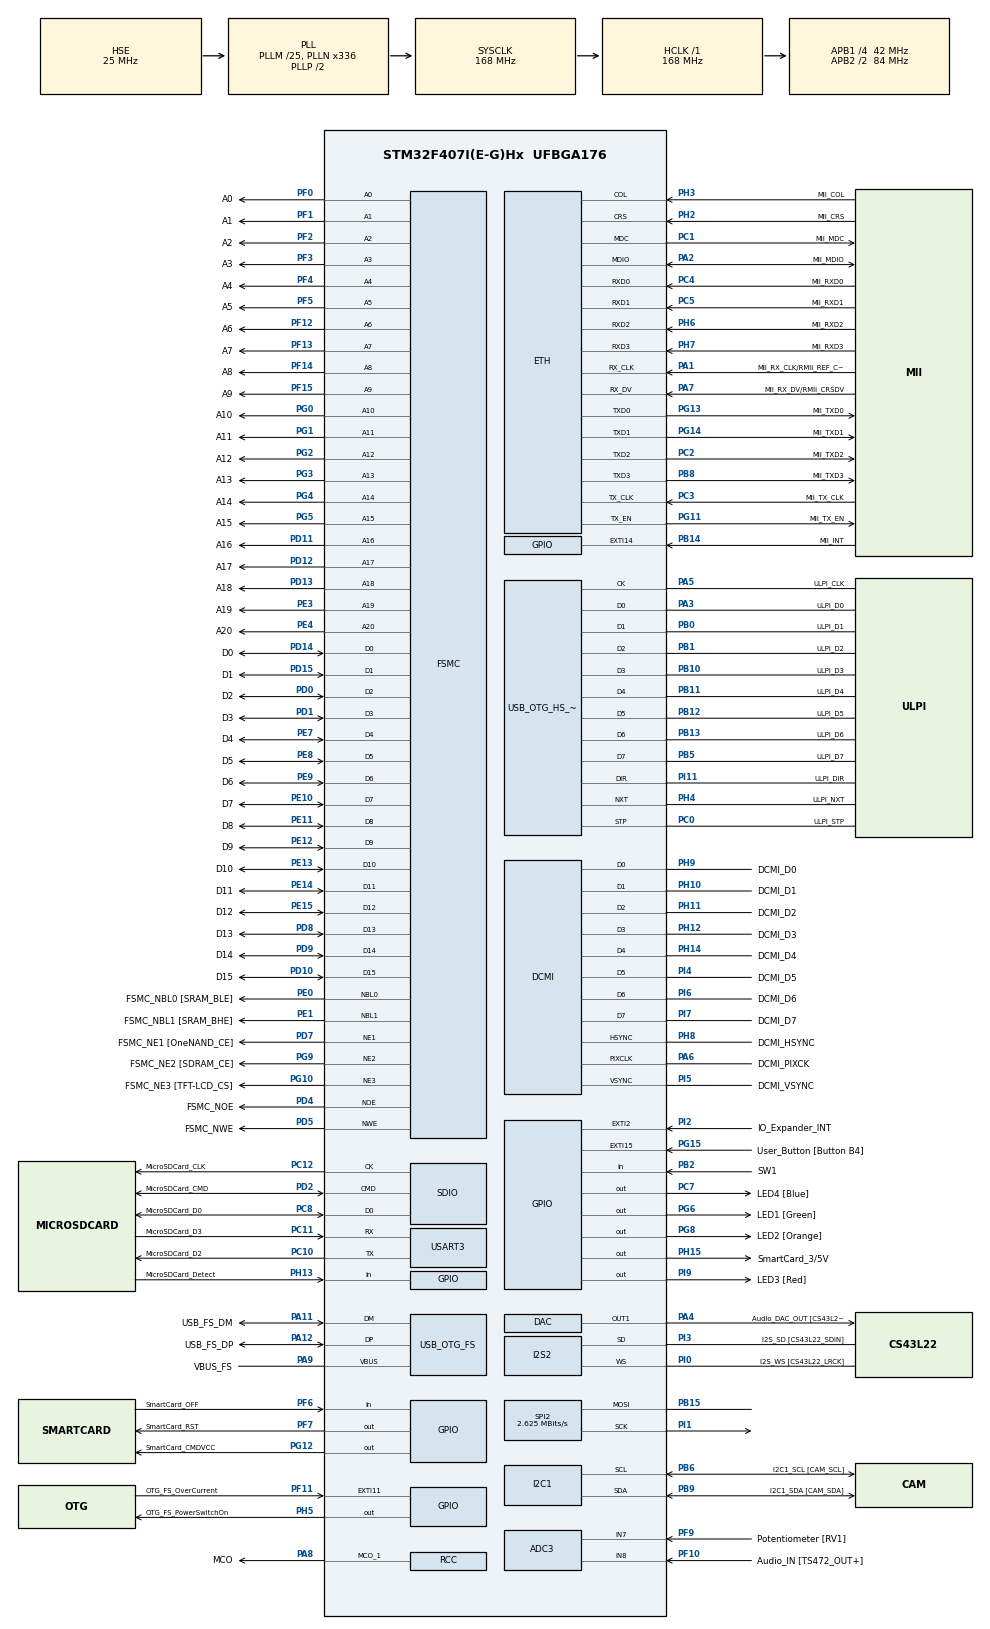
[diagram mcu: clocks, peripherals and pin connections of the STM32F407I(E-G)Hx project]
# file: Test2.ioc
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ADC3.Channel=ADC_CHANNEL_7
ADC3.Channel-0\#ChannelRegularConversion=ADC_CHANNEL_7
ADC3.NbrOfConversionFlag=1
ADC3.Rank-0\#ChannelRegularConversion=1
ADC3.SamplingTime-0\#ChannelRegularConversion=ADC_SAMPLETIME_3CYCLES
Dma.Request0=SPI2_TX
Dma.SPI2_TX.0.Direction=DMA_MEMORY_TO_PERIPH
Dma.SPI2_TX.0.FIFOMode=DMA_FIFOMODE_DISABLE
Dma.SPI2_TX.0.Instance=DMA1_Stream4
Dma.SPI2_TX.0.MemDataAlignment=DMA_MDATAALIGN_BYTE
Dma.SPI2_TX.0.MemInc=DMA_MINC_ENABLE
Dma.SPI2_TX.0.Mode=DMA_CIRCULAR
Dma.SPI2_TX.0.PeriphDataAlignment=DMA_PDATAALIGN_BYTE
Dma.SPI2_TX.0.PeriphInc=DMA_PINC_DISABLE
Dma.SPI2_TX.0.Priority=DMA_PRIORITY_LOW
ETH.MediaInterface=HAL_ETH_MII_MODE
FATFS.BSP.number=1
FATFS0.BSP.STBoard=false
FATFS0.BSP.api=Unknown
FATFS0.BSP.instance=PH13
FATFS0.BSP.ip=GPIO
FATFS0.BSP.mode=Input
FATFS0.BSP.name=Detect_SDIO
FATFS0.BSP.solution=PH13
FREERTOS.Tasks01=defaultTask,0,128,StartDefaultTask,Default,NULL,Dynamic,NULL,NULL
Mcu.Family=STM32F4
Mcu.Name=STM32F407I(E-G)Hx
Mcu.Package=UFBGA176
NVIC.DMA1_Stream4_IRQn=true\:5\:0\:false\:false\:true\:true\:false\:true\:true
NVIC.ETH_IRQn=true\:5\:0\:false\:false\:true\:true\:true\:true\:true
NVIC.OTG_FS_IRQn=true\:5\:0\:false\:false\:true\:true\:true\:true\:true
NVIC.PriorityGroup=NVIC_PRIORITYGROUP_4
PA0-WKUP.GPIO_Label=WAKEUP [Button B2]
PA0-WKUP.Signal=SYS_WKUP
PA1.GPIO_Label=MII_RX_CLK/RMII_REF_CLK
PA1.GPIO_Mode=GPIO_MODE_AF_PP
PA1.GPIO_PuPd=GPIO_NOPULL
PA1.GPIO_Speed=GPIO_SPEED_FREQ_LOW
PA1.Mode=MII
PA1.Signal=ETH_RX_CLK
PA10.GPIO_Label=USB_FS_ID
PA10.GPIO_Mode=GPIO_MODE_AF_PP
PA10.GPIO_PuPd=GPIO_NOPULL
PA10.GPIO_Speed=GPIO_SPEED_FREQ_LOW
PA10.Signal=USB_OTG_FS_ID
PA11.GPIO_Label=USB_FS_DM
PA11.GPIO_Mode=GPIO_MODE_AF_PP
PA11.GPIO_PuPd=GPIO_NOPULL
PA11.GPIO_Speed=GPIO_SPEED_FREQ_LOW
PA11.Mode=Host_Only
PA11.Signal=USB_OTG_FS_DM
PA12.GPIO_Label=USB_FS_DP
PA12.GPIO_Mode=GPIO_MODE_AF_PP
PA12.GPIO_PuPd=GPIO_NOPULL
PA12.GPIO_Speed=GPIO_SPEED_FREQ_LOW
PA12.Mode=Host_Only
PA12.Signal=USB_OTG_FS_DP
PA13.GPIO_Label=TMS/SWDIO
PA13.Mode=Serial_Wire
PA13.Signal=SYS_JTMS-SWDIO
PA14.GPIO_Label=TCK/SWCLK
PA14.Mode=Serial_Wire
PA14.Signal=SYS_JTCK-SWCLK
PA15.GPIO_Label=TDI
PA15.Signal=SYS_JTDI
PA2.GPIO_Label=MII_MDIO
PA2.GPIO_Mode=GPIO_MODE_AF_PP
PA2.GPIO_PuPd=GPIO_NOPULL
PA2.GPIO_Speed=GPIO_SPEED_FREQ_LOW
PA2.Mode=MII
PA2.Signal=ETH_MDIO
PA3.GPIO_Label=ULPI_D0
PA3.GPIO_Mode=GPIO_MODE_AF_PP
PA3.GPIO_PuPd=GPIO_NOPULL
PA3.GPIO_Speed=GPIO_SPEED_FREQ_VERY_HIGH
PA3.Mode=Host_HS
PA3.Signal=USB_OTG_HS_ULPI_D0
PA4.GPIO_Label=Audio_DAC_OUT [CS43L22_AIN1]
PA4.GPIO_Mode=GPIO_MODE_ANALOG
PA4.GPIO_PuPd=GPIO_NOPULL
PA4.Signal=COMP_DAC1_group
PA5.GPIO_Label=ULPI_CLK
PA5.GPIO_Mode=GPIO_MODE_AF_PP
PA5.GPIO_PuPd=GPIO_NOPULL
PA5.GPIO_Speed=GPIO_SPEED_FREQ_VERY_HIGH
PA5.Mode=Host_HS
PA5.Signal=USB_OTG_HS_ULPI_CK
PA6.GPIO_Label=DCMI_PIXCK
PA6.GPIO_Mode=GPIO_MODE_AF_PP
PA6.GPIO_PuPd=GPIO_NOPULL
PA6.GPIO_Speed=GPIO_SPEED_FREQ_LOW
PA6.Mode=Slave_8_bits_External_Synchro
PA6.Signal=DCMI_PIXCLK
PA7.GPIO_Label=MII_RX_DV/RMII_CRSDV
PA7.GPIO_Mode=GPIO_MODE_AF_PP
PA7.GPIO_PuPd=GPIO_NOPULL
PA7.GPIO_Speed=GPIO_SPEED_FREQ_LOW
PA7.Mode=MII
PA7.Signal=ETH_RX_DV
PA8.GPIO_Label=MCO
PA8.GPIO_Mode=GPIO_MODE_AF_PP
PA8.GPIO_PuPd=GPIO_NOPULL
PA8.GPIO_Speed=GPIO_SPEED_FREQ_LOW
PA8.Mode=Clock-out-1
PA8.Signal=RCC_MCO_1
PA9.GPIO_Label=VBUS_FS
PA9.GPIO_Mode=GPIO_MODE_INPUT
PA9.GPIO_PuPd=GPIO_NOPULL
PA9.Mode=Activate_VBUS
PA9.Signal=USB_OTG_FS_VBUS
PB0.GPIO_Label=ULPI_D1
PB0.GPIO_Mode=GPIO_MODE_AF_PP
PB0.GPIO_PuPd=GPIO_NOPULL
PB0.GPIO_Speed=GPIO_SPEED_FREQ_VERY_HIGH
PB0.Mode=Host_HS
PB0.Signal=USB_OTG_HS_ULPI_D1
PB1.GPIO_Label=ULPI_D2
PB1.GPIO_Mode=GPIO_MODE_AF_PP
PB1.GPIO_PuPd=GPIO_NOPULL
PB1.GPIO_Speed=GPIO_SPEED_FREQ_VERY_HIGH
PB1.Mode=Host_HS
PB1.Signal=USB_OTG_HS_ULPI_D2
PB10.GPIO_Label=ULPI_D3
PB10.GPIO_Mode=GPIO_MODE_AF_PP
PB10.GPIO_PuPd=GPIO_NOPULL
PB10.GPIO_Speed=GPIO_SPEED_FREQ_VERY_HIGH
PB10.Mode=Host_HS
PB10.Signal=USB_OTG_HS_ULPI_D3
PB11.GPIO_Label=ULPI_D4
PB11.GPIO_Mode=GPIO_MODE_AF_PP
PB11.GPIO_PuPd=GPIO_NOPULL
PB11.GPIO_Speed=GPIO_SPEED_FREQ_VERY_HIGH
PB11.Mode=Host_HS
PB11.Signal=USB_OTG_HS_ULPI_D4
PB12.GPIO_Label=ULPI_D5
PB12.GPIO_Mode=GPIO_MODE_AF_PP
PB12.GPIO_PuPd=GPIO_NOPULL
PB12.GPIO_Speed=GPIO_SPEED_FREQ_VERY_HIGH
PB12.Mode=Host_HS
PB12.Signal=USB_OTG_HS_ULPI_D5
PB13.GPIO_Label=ULPI_D6
PB13.GPIO_Mode=GPIO_MODE_AF_PP
PB13.GPIO_PuPd=GPIO_NOPULL
PB13.GPIO_Speed=GPIO_SPEED_FREQ_VERY_HIGH
PB13.Mode=Host_HS
PB13.Signal=USB_OTG_HS_ULPI_D6
PB14.GPIO_Label=MII_INT
PB14.GPIO_ModeDefaultEXTI=GPIO_MODE_EVT_RISING
PB14.GPIO_PuPd=GPIO_NOPULL
PB14.Signal=GPXTI14
PB15.Mode=Simplex_Bidirectional_Master
PB15.Signal=SPI2_MOSI
PB2.GPIO_Label=SW1
PB2.GPIO_Mode=GPIO_MODE_INPUT
PB2.GPIO_PuPd=GPIO_NOPULL
PB2.Signal=GPIO_Input
PB3.GPIO_Label=TDO/SWO
PB3.Signal=SYS_JTDO-SWO
PB4.GPIO_Label=TRST
PB4.Signal=SYS_JTRST
PB5.GPIO_Label=ULPI_D7
PB5.GPIO_Mode=GPIO_MODE_AF_PP
PB5.GPIO_PuPd=GPIO_NOPULL
PB5.GPIO_Speed=GPIO_SPEED_FREQ_VERY_HIGH
PB5.Mode=Host_HS
PB5.Signal=USB_OTG_HS_ULPI_D7
PB6.GPIO_Label=I2C1_SCL [CAM_SCL]
PB6.GPIO_Mode=GPIO_MODE_AF_OD
PB6.GPIO_Pu=GPIO_PULLUP
PB6.GPIO_PuPd=GPIO_NOPULL
PB6.GPIO_Speed=GPIO_SPEED_FREQ_LOW
PB6.Mode=I2C
PB6.Signal=I2C1_SCL
PB7.GPIO_Label=FSMC_NL [OneNAND_AVD]
PB7.GPIO_Mode=GPIO_MODE_AF_PP
PB7.GPIO_PuPd=GPIO_NOPULL
PB7.GPIO_Speed=GPIO_SPEED_FREQ_LOW
PB7.Signal=FSMC_NL
PB8.GPIO_Label=MII_TXD3
PB8.GPIO_Mode=GPIO_MODE_AF_PP
PB8.GPIO_PuPd=GPIO_NOPULL
PB8.GPIO_Speed=GPIO_SPEED_FREQ_LOW
PB8.Mode=MII
PB8.Signal=ETH_TXD3
PB9.GPIO_Label=I2C1_SDA [CAM_SDA]
PB9.GPIO_Mode=GPIO_MODE_AF_OD
PB9.GPIO_Pu=GPIO_PULLUP
PB9.GPIO_PuPd=GPIO_NOPULL
PB9.GPIO_Speed=GPIO_SPEED_FREQ_LOW
PB9.Mode=I2C
PB9.Signal=I2C1_SDA
PC0.GPIO_Label=ULPI_STP
PC0.GPIO_Mode=GPIO_MODE_AF_PP
PC0.GPIO_PuPd=GPIO_NOPULL
PC0.GPIO_Speed=GPIO_SPEED_FREQ_VERY_HIGH
PC0.Mode=Host_HS
PC0.Signal=USB_OTG_HS_ULPI_STP
PC1.GPIO_Label=MII_MDC
PC1.GPIO_Mode=GPIO_MODE_AF_PP
PC1.GPIO_PuPd=GPIO_NOPULL
PC1.GPIO_Speed=GPIO_SPEED_FREQ_LOW
PC1.Mode=MII
PC1.Signal=ETH_MDC
PC10.GPIO_Label=MicroSDCard_D2
PC10.GPIO_Mode=GPIO_MODE_AF_PP
PC10.GPIO_PuPd=GPIO_NOPULL
PC10.GPIO_Speed=GPIO_SPEED_FREQ_LOW
PC10.Mode=Asynchronous
PC10.Signal=USART3_TX
PC11.GPIO_Label=MicroSDCard_D3
PC11.GPIO_Mode=GPIO_MODE_AF_PP
PC11.GPIO_PuPd=GPIO_NOPULL
PC11.GPIO_Speed=GPIO_SPEED_FREQ_LOW
PC11.Mode=Asynchronous
PC11.Signal=USART3_RX
PC12.GPIO_Label=MicroSDCard_CLK
PC12.GPIO_Mode=GPIO_MODE_AF_PP
PC12.GPIO_PuPd=GPIO_NOPULL
PC12.GPIO_Speed=GPIO_SPEED_FREQ_LOW
PC12.Mode=SD_1_bit
PC12.Signal=SDIO_CK
PC13-ANTI_TAMP.GPIO_Label=Anti_Tamper [Button B3]
PC13-ANTI_TAMP.Signal=RTC_AF1
PC14-OSC32_IN.GPIO_Label=PC14-OSC32_IN
PC14-OSC32_IN.Mode=LSE-External-Oscillator
PC14-OSC32_IN.Signal=RCC_OSC32_IN
PC15-OSC32_OUT.GPIO_Label=PC15-OSC32_OUT
PC15-OSC32_OUT.Mode=LSE-External-Oscillator
PC15-OSC32_OUT.Signal=RCC_OSC32_OUT
PC2.GPIO_Label=MII_TXD2
PC2.GPIO_Mode=GPIO_MODE_AF_PP
PC2.GPIO_PuPd=GPIO_NOPULL
PC2.GPIO_Speed=GPIO_SPEED_FREQ_LOW
PC2.Mode=MII
PC2.Signal=ETH_TXD2
PC3.GPIO_Label=MII_TX_CLK
PC3.GPIO_Mode=GPIO_MODE_AF_PP
PC3.GPIO_PuPd=GPIO_NOPULL
PC3.GPIO_Speed=GPIO_SPEED_FREQ_LOW
PC3.Mode=MII
PC3.Signal=ETH_TX_CLK
PC4.GPIO_Label=MII_RXD0
PC4.GPIO_Mode=GPIO_MODE_AF_PP
PC4.GPIO_PuPd=GPIO_NOPULL
PC4.GPIO_Speed=GPIO_SPEED_FREQ_LOW
PC4.Mode=MII
PC4.Signal=ETH_RXD0
PC5.GPIO_Label=MII_RXD1
PC5.GPIO_Mode=GPIO_MODE_AF_PP
PC5.GPIO_PuPd=GPIO_NOPULL
PC5.GPIO_Speed=GPIO_SPEED_FREQ_LOW
PC5.Mode=MII
PC5.Signal=ETH_RXD1
PC7.GPIO_Label=LED4 [Blue]
PC7.GPIO_Mode=GPIO_MODE_OUTPUT_PP
PC7.GPIO_ModeDefaultOutputPP=GPIO_MODE_OUTPUT_PP
PC7.GPIO_PuPd=GPIO_NOPULL
PC7.GPIO_Speed=GPIO_SPEED_FREQ_LOW
PC7.Signal=GPIO_Output
PC8.GPIO_Label=MicroSDCard_D0
PC8.GPIO_Mode=GPIO_MODE_AF_PP
PC8.GPIO_PuPd=GPIO_NOPULL
PC8.GPIO_Speed=GPIO_SPEED_FREQ_LOW
PC8.Mode=SD_1_bit
PC8.Signal=SDIO_D0
PC9.GPIO_Label=MicroSDCard_D1
PC9.GPIO_Mode=GPIO_MODE_AF_PP
PC9.GPIO_PuPd=GPIO_NOPULL
PC9.GPIO_Speed=GPIO_SPEED_FREQ_LOW
PC9.Signal=SDIO_D1
PD0.GPIO_Label=D2
PD0.GPIO_Mode=GPIO_MODE_AF_PP
PD0.GPIO_PuPd=GPIO_NOPULL
PD0.GPIO_Speed=GPIO_SPEED_FREQ_LOW
PD0.Signal=FSMC_D2_DA2
PD1.GPIO_Label=D3
PD1.GPIO_Mode=GPIO_MODE_AF_PP
PD1.GPIO_PuPd=GPIO_NOPULL
PD1.GPIO_Speed=GPIO_SPEED_FREQ_LOW
PD1.Signal=FSMC_D3_DA3
PD10.GPIO_Label=D15
PD10.GPIO_Mode=GPIO_MODE_AF_PP
PD10.GPIO_PuPd=GPIO_NOPULL
PD10.GPIO_Speed=GPIO_SPEED_FREQ_LOW
PD10.Signal=FSMC_D15_DA15
PD11.GPIO_Label=A16
PD11.GPIO_Mode=GPIO_MODE_AF_PP
PD11.GPIO_PuPd=GPIO_NOPULL
PD11.GPIO_Speed=GPIO_SPEED_FREQ_LOW
PD11.Signal=FSMC_A16_CLE
PD12.GPIO_Label=A17
PD12.GPIO_Mode=GPIO_MODE_AF_PP
PD12.GPIO_PuPd=GPIO_NOPULL
PD12.GPIO_Speed=GPIO_SPEED_FREQ_LOW
PD12.Signal=FSMC_A17_ALE
PD13.GPIO_Label=A18
PD13.GPIO_Mode=GPIO_MODE_AF_PP
PD13.GPIO_PuPd=GPIO_NOPULL
PD13.GPIO_Speed=GPIO_SPEED_FREQ_LOW
PD13.Signal=FSMC_A18
PD14.GPIO_Label=D0
PD14.GPIO_Mode=GPIO_MODE_AF_PP
PD14.GPIO_PuPd=GPIO_NOPULL
PD14.GPIO_Speed=GPIO_SPEED_FREQ_LOW
PD14.Signal=FSMC_D0_DA0
PD15.GPIO_Label=D1
PD15.GPIO_Mode=GPIO_MODE_AF_PP
PD15.GPIO_PuPd=GPIO_NOPULL
PD15.GPIO_Speed=GPIO_SPEED_FREQ_LOW
PD15.Signal=FSMC_D1_DA1
PD2.GPIO_Label=MicroSDCard_CMD
PD2.GPIO_Mode=GPIO_MODE_AF_PP
PD2.GPIO_PuPd=GPIO_NOPULL
PD2.GPIO_Speed=GPIO_SPEED_FREQ_LOW
PD2.Mode=SD_1_bit
PD2.Signal=SDIO_CMD
PD3.GPIO_Label=FSMC_CLK [OneNAND_CLK]
PD3.GPIO_Mode=GPIO_MODE_AF_PP
PD3.GPIO_PuPd=GPIO_NOPULL
PD3.GPIO_Speed=GPIO_SPEED_FREQ_LOW
PD3.Signal=FSMC_CLK
PD4.GPIO_Label=FSMC_NOE
PD4.GPIO_Mode=GPIO_MODE_AF_PP
PD4.GPIO_PuPd=GPIO_NOPULL
PD4.GPIO_Speed=GPIO_SPEED_FREQ_LOW
PD4.Signal=FSMC_NOE
PD5.GPIO_Label=FSMC_NWE
PD5.GPIO_Mode=GPIO_MODE_AF_PP
PD5.GPIO_PuPd=GPIO_NOPULL
PD5.GPIO_Speed=GPIO_SPEED_FREQ_LOW
PD5.Signal=FSMC_NWE
PD6.GPIO_Label=FSMC_NWAIT [OneNAND_RDY]
PD6.GPIO_Mode=GPIO_MODE_AF_PP
PD6.GPIO_PuPd=GPIO_NOPULL
PD6.GPIO_Speed=GPIO_SPEED_FREQ_LOW
PD6.Signal=FSMC_NWAIT
PD7.GPIO_Label=FSMC_NE1 [OneNAND_CE]
PD7.GPIO_Mode=GPIO_MODE_AF_PP
PD7.GPIO_PuPd=GPIO_NOPULL
PD7.GPIO_Speed=GPIO_SPEED_FREQ_LOW
PD7.Mode=NorPsramChipSelect1_1
PD7.Signal=FSMC_NE1
PD8.GPIO_Label=D13
PD8.GPIO_Mode=GPIO_MODE_AF_PP
PD8.GPIO_PuPd=GPIO_NOPULL
PD8.GPIO_Speed=GPIO_SPEED_FREQ_LOW
PD8.Signal=FSMC_D13_DA13
PD9.GPIO_Label=D14
PD9.GPIO_Mode=GPIO_MODE_AF_PP
PD9.GPIO_PuPd=GPIO_NOPULL
PD9.GPIO_Speed=GPIO_SPEED_FREQ_LOW
PD9.Signal=FSMC_D14_DA14
PE0.GPIO_Label=FSMC_NBL0 [SRAM_BLE]
PE0.GPIO_Mode=GPIO_MODE_AF_PP
PE0.GPIO_PuPd=GPIO_NOPULL
PE0.GPIO_Speed=GPIO_SPEED_FREQ_LOW
PE0.Signal=FSMC_NBL0
PE1.GPIO_Label=FSMC_NBL1 [SRAM_BHE]
PE1.GPIO_Mode=GPIO_MODE_AF_PP
PE1.GPIO_PuPd=GPIO_NOPULL
PE1.GPIO_Speed=GPIO_SPEED_FREQ_LOW
PE1.Signal=FSMC_NBL1
PE10.GPIO_Label=D7
PE10.GPIO_Mode=GPIO_MODE_AF_PP
PE10.GPIO_PuPd=GPIO_NOPULL
PE10.GPIO_Speed=GPIO_SPEED_FREQ_LOW
PE10.Signal=FSMC_D7_DA7
PE11.GPIO_Label=D8
PE11.GPIO_Mode=GPIO_MODE_AF_PP
PE11.GPIO_PuPd=GPIO_NOPULL
PE11.GPIO_Speed=GPIO_SPEED_FREQ_LOW
PE11.Signal=FSMC_D8_DA8
PE12.GPIO_Label=D9
PE12.GPIO_Mode=GPIO_MODE_AF_PP
PE12.GPIO_PuPd=GPIO_NOPULL
PE12.GPIO_Speed=GPIO_SPEED_FREQ_LOW
PE12.Signal=FSMC_D9_DA9
PE13.GPIO_Label=D10
PE13.GPIO_Mode=GPIO_MODE_AF_PP
PE13.GPIO_PuPd=GPIO_NOPULL
PE13.GPIO_Speed=GPIO_SPEED_FREQ_LOW
PE13.Signal=FSMC_D10_DA10
PE14.GPIO_Label=D11
PE14.GPIO_Mode=GPIO_MODE_AF_PP
PE14.GPIO_PuPd=GPIO_NOPULL
PE14.GPIO_Speed=GPIO_SPEED_FREQ_LOW
PE14.Signal=FSMC_D11_DA11
PE15.GPIO_Label=D12
PE15.GPIO_Mode=GPIO_MODE_AF_PP
PE15.GPIO_PuPd=GPIO_NOPULL
PE15.GPIO_Speed=GPIO_SPEED_FREQ_LOW
PE15.Signal=FSMC_D12_DA12
PE2.GPIO_Label=TRACE_CLK
PE2.Signal=SYS_TRACECLK
PE3.GPIO_Label=A19
PE3.GPIO_Mode=GPIO_MODE_AF_PP
PE3.GPIO_PuPd=GPIO_NOPULL
PE3.GPIO_Speed=GPIO_SPEED_FREQ_LOW
PE3.Signal=FSMC_A19
PE4.GPIO_Label=A20
PE4.GPIO_Mode=GPIO_MODE_AF_PP
PE4.GPIO_PuPd=GPIO_NOPULL
PE4.GPIO_Speed=GPIO_SPEED_FREQ_LOW
PE4.Signal=FSMC_A20
PE5.GPIO_Label=TRACE_D2
PE5.Signal=SYS_TRACED2
PE6.GPIO_Label=TRACE_D3
PE6.Signal=SYS_TRACED3
PE7.GPIO_Label=D4
PE7.GPIO_Mode=GPIO_MODE_AF_PP
PE7.GPIO_PuPd=GPIO_NOPULL
PE7.GPIO_Speed=GPIO_SPEED_FREQ_LOW
PE7.Signal=FSMC_D4_DA4
PE8.GPIO_Label=D5
PE8.GPIO_Mode=GPIO_MODE_AF_PP
PE8.GPIO_PuPd=GPIO_NOPULL
PE8.GPIO_Speed=GPIO_SPEED_FREQ_LOW
PE8.Signal=FSMC_D5_DA5
PE9.GPIO_Label=D6
PE9.GPIO_Mode=GPIO_MODE_AF_PP
PE9.GPIO_PuPd=GPIO_NOPULL
PE9.GPIO_Speed=GPIO_SPEED_FREQ_LOW
PE9.Signal=FSMC_D6_DA6
PF0.GPIO_Label=A0
PF0.GPIO_Mode=GPIO_MODE_AF_PP
PF0.GPIO_PuPd=GPIO_NOPULL
PF0.GPIO_Speed=GPIO_SPEED_FREQ_LOW
PF0.Signal=FSMC_A0
PF1.GPIO_Label=A1
PF1.GPIO_Mode=GPIO_MODE_AF_PP
PF1.GPIO_PuPd=GPIO_NOPULL
PF1.GPIO_Speed=GPIO_SPEED_FREQ_LOW
PF1.Signal=FSMC_A1
PF10.GPIO_Label=Audio_IN [TS472_OUT+]
PF10.GPIO_Mode=GPIO_MODE_ANALOG
PF10.GPIO_PuPd=GPIO_NOPULL
PF10.Mode=IN8
PF10.Signal=ADC3_IN8
PF11.GPIO_Label=OTG_FS_OverCurrent
PF11.GPIO_ModeDefaultEXTI=GPIO_MODE_EVT_RISING
PF11.GPIO_PuPd=GPIO_NOPULL
PF11.Signal=GPXTI11
PF12.GPIO_Label=A6
PF12.GPIO_Mode=GPIO_MODE_AF_PP
PF12.GPIO_PuPd=GPIO_NOPULL
PF12.GPIO_Speed=GPIO_SPEED_FREQ_LOW
PF12.Signal=FSMC_A6
PF13.GPIO_Label=A7
PF13.GPIO_Mode=GPIO_MODE_AF_PP
PF13.GPIO_PuPd=GPIO_NOPULL
PF13.GPIO_Speed=GPIO_SPEED_FREQ_LOW
PF13.Signal=FSMC_A7
PF14.GPIO_Label=A8
PF14.GPIO_Mode=GPIO_MODE_AF_PP
PF14.GPIO_PuPd=GPIO_NOPULL
PF14.GPIO_Speed=GPIO_SPEED_FREQ_LOW
PF14.Signal=FSMC_A8
PF15.GPIO_Label=A9
PF15.GPIO_Mode=GPIO_MODE_AF_PP
PF15.GPIO_PuPd=GPIO_NOPULL
PF15.GPIO_Speed=GPIO_SPEED_FREQ_LOW
PF15.Signal=FSMC_A9
PF2.GPIO_Label=A2
PF2.GPIO_Mode=GPIO_MODE_AF_PP
PF2.GPIO_PuPd=GPIO_NOPULL
PF2.GPIO_Speed=GPIO_SPEED_FREQ_LOW
PF2.Signal=FSMC_A2
PF3.GPIO_Label=A3
PF3.GPIO_Mode=GPIO_MODE_AF_PP
PF3.GPIO_PuPd=GPIO_NOPULL
PF3.GPIO_Speed=GPIO_SPEED_FREQ_LOW
PF3.Signal=FSMC_A3
PF4.GPIO_Label=A4
PF4.GPIO_Mode=GPIO_MODE_AF_PP
PF4.GPIO_PuPd=GPIO_NOPULL
PF4.GPIO_Speed=GPIO_SPEED_FREQ_LOW
PF4.Signal=FSMC_A4
PF5.GPIO_Label=A5
PF5.GPIO_Mode=GPIO_MODE_AF_PP
PF5.GPIO_PuPd=GPIO_NOPULL
PF5.GPIO_Speed=GPIO_SPEED_FREQ_LOW
PF5.Signal=FSMC_A5
PF6.GPIO_Label=SmartCard_OFF
PF6.GPIO_Mode=GPIO_MODE_INPUT
PF6.GPIO_PuPd=GPIO_NOPULL
PF6.Signal=GPIO_Input
PF7.GPIO_Label=SmartCard_RST
PF7.GPIO_Mode=GPIO_MODE_OUTPUT_PP
PF7.GPIO_ModeDefaultOutputPP=GPIO_MODE_OUTPUT_PP
PF7.GPIO_PuPd=GPIO_NOPULL
PF7.GPIO_Speed=GPIO_SPEED_FREQ_LOW
PF7.Signal=GPIO_Output
PF9.GPIO_Label=Potentiometer [RV1]
PF9.GPIO_Mode=GPIO_MODE_ANALOG
PF9.GPIO_PuPd=GPIO_NOPULL
PF9.Mode=IN7
PF9.Signal=ADC3_IN7
PG0.GPIO_Label=A10
PG0.GPIO_Mode=GPIO_MODE_AF_PP
PG0.GPIO_PuPd=GPIO_NOPULL
PG0.GPIO_Speed=GPIO_SPEED_FREQ_LOW
PG0.Signal=FSMC_A10
PG1.GPIO_Label=A11
PG1.GPIO_Mode=GPIO_MODE_AF_PP
PG1.GPIO_PuPd=GPIO_NOPULL
PG1.GPIO_Speed=GPIO_SPEED_FREQ_LOW
PG1.Signal=FSMC_A11
PG10.GPIO_Label=FSMC_NE3 [TFT-LCD_CS]
PG10.GPIO_Mode=GPIO_MODE_AF_PP
PG10.GPIO_PuPd=GPIO_NOPULL
PG10.GPIO_Speed=GPIO_SPEED_FREQ_LOW
PG10.Mode=NorPsramChipSelect3_3
PG10.Signal=FSMC_NE3
PG11.GPIO_Label=MII_TX_EN
PG11.GPIO_Mode=GPIO_MODE_AF_PP
PG11.GPIO_PuPd=GPIO_NOPULL
PG11.GPIO_Speed=GPIO_SPEED_FREQ_LOW
PG11.Mode=MII
PG11.Signal=ETH_TX_EN
PG12.GPIO_Label=SmartCard_CMDVCC
PG12.GPIO_Mode=GPIO_MODE_OUTPUT_PP
PG12.GPIO_ModeDefaultOutputPP=GPIO_MODE_OUTPUT_PP
PG12.GPIO_PuPd=GPIO_NOPULL
PG12.GPIO_Speed=GPIO_SPEED_FREQ_LOW
PG12.Signal=GPIO_Output
PG13.GPIO_Label=MII_TXD0
PG13.GPIO_Mode=GPIO_MODE_AF_PP
PG13.GPIO_PuPd=GPIO_NOPULL
PG13.GPIO_Speed=GPIO_SPEED_FREQ_LOW
PG13.Mode=MII
PG13.Signal=ETH_TXD0
PG14.GPIO_Label=MII_TXD1
PG14.GPIO_Mode=GPIO_MODE_AF_PP
PG14.GPIO_PuPd=GPIO_NOPULL
PG14.GPIO_Speed=GPIO_SPEED_FREQ_LOW
PG14.Mode=MII
PG14.Signal=ETH_TXD1
PG15.GPIO_Label=User_Button [Button B4]
PG15.GPIO_ModeDefaultEXTI=GPIO_MODE_EVT_RISING
PG15.GPIO_PuPd=GPIO_NOPULL
PG15.Signal=GPXTI15
PG2.GPIO_Label=A12
PG2.GPIO_Mode=GPIO_MODE_AF_PP
PG2.GPIO_PuPd=GPIO_NOPULL
PG2.GPIO_Speed=GPIO_SPEED_FREQ_LOW
PG2.Signal=FSMC_A12
PG3.GPIO_Label=A13
PG3.GPIO_Mode=GPIO_MODE_AF_PP
PG3.GPIO_PuPd=GPIO_NOPULL
PG3.GPIO_Speed=GPIO_SPEED_FREQ_LOW
PG3.Signal=FSMC_A13
PG4.GPIO_Label=A14
PG4.GPIO_Mode=GPIO_MODE_AF_PP
PG4.GPIO_PuPd=GPIO_NOPULL
PG4.GPIO_Speed=GPIO_SPEED_FREQ_LOW
PG4.Signal=FSMC_A14
PG5.GPIO_Label=A15
PG5.GPIO_Mode=GPIO_MODE_AF_PP
PG5.GPIO_PuPd=GPIO_NOPULL
PG5.GPIO_Speed=GPIO_SPEED_FREQ_LOW
PG5.Signal=FSMC_A15
PG6.GPIO_Label=LED1 [Green]
PG6.GPIO_Mode=GPIO_MODE_OUTPUT_PP
PG6.GPIO_ModeDefaultOutputPP=GPIO_MODE_OUTPUT_PP
PG6.GPIO_PuPd=GPIO_NOPULL
PG6.GPIO_Speed=GPIO_SPEED_FREQ_LOW
PG6.Signal=GPIO_Output
PG7.GPIO_Label=SmartCard_CLK
PG7.GPIO_Mode=GPIO_MODE_AF_PP
PG7.GPIO_PuPd=GPIO_NOPULL
PG7.GPIO_Speed=GPIO_SPEED_FREQ_LOW
PG7.Signal=USART6_CK
PG8.GPIO_Label=LED2 [Orange]
PG8.GPIO_Mode=GPIO_MODE_OUTPUT_PP
PG8.GPIO_ModeDefaultOutputPP=GPIO_MODE_OUTPUT_PP
PG8.GPIO_PuPd=GPIO_NOPULL
PG8.GPIO_Speed=GPIO_SPEED_FREQ_LOW
PG8.Signal=GPIO_Output
PG9.GPIO_Label=FSMC_NE2 [SDRAM_CE]
PG9.GPIO_Mode=GPIO_MODE_AF_PP
PG9.GPIO_PuPd=GPIO_NOPULL
PG9.GPIO_Speed=GPIO_SPEED_FREQ_LOW
PG9.Mode=NorPsramChipSelect2_2
PG9.Signal=FSMC_NE2
PH0-OSC_IN.GPIO_Label=PH0-OSC_IN
PH0-OSC_IN.Mode=HSE-External-Oscillator
PH0-OSC_IN.Signal=RCC_OSC_IN
PH1-OSC_OUT.GPIO_Label=PH1-OSC_OUT
PH1-OSC_OUT.Mode=HSE-External-Oscillator
PH1-OSC_OUT.Signal=RCC_OSC_OUT
PH10.GPIO_Label=DCMI_D1
PH10.GPIO_Mode=GPIO_MODE_AF_PP
PH10.GPIO_PuPd=GPIO_NOPULL
PH10.GPIO_Speed=GPIO_SPEED_FREQ_LOW
PH10.Mode=Slave_8_bits_External_Synchro
PH10.Signal=DCMI_D1
PH11.GPIO_Label=DCMI_D2
PH11.GPIO_Mode=GPIO_MODE_AF_PP
PH11.GPIO_PuPd=GPIO_NOPULL
PH11.GPIO_Speed=GPIO_SPEED_FREQ_LOW
PH11.Mode=Slave_8_bits_External_Synchro
PH11.Signal=DCMI_D2
PH12.GPIO_Label=DCMI_D3
PH12.GPIO_Mode=GPIO_MODE_AF_PP
PH12.GPIO_PuPd=GPIO_NOPULL
PH12.GPIO_Speed=GPIO_SPEED_FREQ_LOW
PH12.Mode=Slave_8_bits_External_Synchro
PH12.Signal=DCMI_D3
PH13.GPIO_Label=MicroSDCard_Detect
PH13.GPIO_Mode=GPIO_MODE_INPUT
PH13.GPIO_PuPd=GPIO_PULLUP
PH13.Signal=GPIO_Input
PH14.GPIO_Label=DCMI_D4
PH14.GPIO_Mode=GPIO_MODE_AF_PP
PH14.GPIO_PuPd=GPIO_NOPULL
PH14.GPIO_Speed=GPIO_SPEED_FREQ_LOW
PH14.Mode=Slave_8_bits_External_Synchro
PH14.Signal=DCMI_D4
PH15.GPIO_Label=SmartCard_3/5V
PH15.GPIO_Mode=GPIO_MODE_OUTPUT_PP
PH15.GPIO_ModeDefaultOutputPP=GPIO_MODE_OUTPUT_PP
PH15.GPIO_PuPd=GPIO_NOPULL
PH15.GPIO_Speed=GPIO_SPEED_FREQ_LOW
PH15.Signal=GPIO_Output
PH2.GPIO_Label=MII_CRS
PH2.GPIO_Mode=GPIO_MODE_AF_PP
PH2.GPIO_PuPd=GPIO_NOPULL
PH2.GPIO_Speed=GPIO_SPEED_FREQ_LOW
PH2.Mode=MII
PH2.Signal=ETH_CRS
PH3.GPIO_Label=MII_COL
PH3.GPIO_Mode=GPIO_MODE_AF_PP
PH3.GPIO_PuPd=GPIO_NOPULL
PH3.GPIO_Speed=GPIO_SPEED_FREQ_LOW
PH3.Mode=MII
PH3.Signal=ETH_COL
PH4.GPIO_Label=ULPI_NXT
PH4.GPIO_Mode=GPIO_MODE_AF_PP
PH4.GPIO_PuPd=GPIO_NOPULL
PH4.GPIO_Speed=GPIO_SPEED_FREQ_VERY_HIGH
PH4.Mode=Host_HS
PH4.Signal=USB_OTG_HS_ULPI_NXT
PH5.GPIO_Label=OTG_FS_PowerSwitchOn
PH5.GPIO_Mode=GPIO_MODE_OUTPUT_PP
PH5.GPIO_ModeDefaultOutputPP=GPIO_MODE_OUTPUT_PP
PH5.GPIO_PuPd=GPIO_NOPULL
PH5.GPIO_Speed=GPIO_SPEED_FREQ_LOW
PH5.Signal=GPIO_Output
PH6.GPIO_Label=MII_RXD2
PH6.GPIO_Mode=GPIO_MODE_AF_PP
PH6.GPIO_PuPd=GPIO_NOPULL
PH6.GPIO_Speed=GPIO_SPEED_FREQ_LOW
PH6.Mode=MII
PH6.Signal=ETH_RXD2
PH7.GPIO_Label=MII_RXD3
PH7.GPIO_Mode=GPIO_MODE_AF_PP
PH7.GPIO_PuPd=GPIO_NOPULL
PH7.GPIO_Speed=GPIO_SPEED_FREQ_LOW
PH7.Mode=MII
PH7.Signal=ETH_RXD3
PH8.GPIO_Label=DCMI_HSYNC
PH8.GPIO_Mode=GPIO_MODE_AF_PP
PH8.GPIO_PuPd=GPIO_NOPULL
PH8.GPIO_Speed=GPIO_SPEED_FREQ_LOW
PH8.Mode=Slave_8_bits_External_Synchro
PH8.Signal=DCMI_HSYNC
PH9.GPIO_Label=DCMI_D0
PH9.GPIO_Mode=GPIO_MODE_AF_PP
PH9.GPIO_PuPd=GPIO_NOPULL
PH9.GPIO_Speed=GPIO_SPEED_FREQ_LOW
PH9.Mode=Slave_8_bits_External_Synchro
PH9.Signal=DCMI_D0
PI0.GPIO_Label=I2S_WS [CS43L22_LRCK]
PI0.GPIO_Mode=GPIO_MODE_AF_PP
PI0.GPIO_PuPd=GPIO_NOPULL
PI0.GPIO_Speed=GPIO_SPEED_FREQ_LOW
PI0.Mode=Half_Duplex_Master
PI0.Signal=I2S2_WS
PI1.Mode=Simplex_Bidirectional_Master
PI1.Signal=SPI2_SCK
PI10.GPIO_Label=MII_RX_ER
PI10.GPIO_Mode=GPIO_MODE_AF_PP
PI10.GPIO_PuPd=GPIO_NOPULL
PI10.GPIO_Speed=GPIO_SPEED_FREQ_LOW
PI10.Signal=ETH_RX_ER
PI11.GPIO_Label=ULPI_DIR
PI11.GPIO_Mode=GPIO_MODE_AF_PP
PI11.GPIO_PuPd=GPIO_NOPULL
PI11.GPIO_Speed=GPIO_SPEED_FREQ_VERY_HIGH
PI11.Mode=Host_HS
PI11.Signal=USB_OTG_HS_ULPI_DIR
PI2.GPIO_Label=IO_Expander_INT
PI2.GPIO_ModeDefaultEXTI=GPIO_MODE_EVT_RISING
PI2.GPIO_PuPd=GPIO_NOPULL
PI2.Signal=GPXTI2
PI3.GPIO_Label=I2S_SD [CS43L22_SDIN]
PI3.GPIO_Mode=GPIO_MODE_AF_PP
PI3.GPIO_PuPd=GPIO_NOPULL
PI3.GPIO_Speed=GPIO_SPEED_FREQ_LOW
PI3.Mode=Half_Duplex_Master
PI3.Signal=I2S2_SD
PI4.GPIO_Label=DCMI_D5
PI4.GPIO_Mode=GPIO_MODE_AF_PP
PI4.GPIO_PuPd=GPIO_NOPULL
PI4.GPIO_Speed=GPIO_SPEED_FREQ_LOW
PI4.Mode=Slave_8_bits_External_Synchro
PI4.Signal=DCMI_D5
PI5.GPIO_Label=DCMI_VSYNC
PI5.GPIO_Mode=GPIO_MODE_AF_PP
PI5.GPIO_PuPd=GPIO_NOPULL
PI5.GPIO_Speed=GPIO_SPEED_FREQ_LOW
PI5.Mode=Slave_8_bits_External_Synchro
PI5.Signal=DCMI_VSYNC
PI6.GPIO_Label=DCMI_D6
PI6.GPIO_Mode=GPIO_MODE_AF_PP
PI6.GPIO_PuPd=GPIO_NOPULL
PI6.GPIO_Speed=GPIO_SPEED_FREQ_LOW
PI6.Mode=Slave_8_bits_External_Synchro
PI6.Signal=DCMI_D6
PI7.GPIO_Label=DCMI_D7
PI7.GPIO_Mode=GPIO_MODE_AF_PP
PI7.GPIO_PuPd=GPIO_NOPULL
PI7.GPIO_Speed=GPIO_SPEED_FREQ_LOW
PI7.Mode=Slave_8_bits_External_Synchro
PI7.Signal=DCMI_D7
PI9.GPIO_Label=LED3 [Red]
PI9.GPIO_Mode=GPIO_MODE_OUTPUT_PP
PI9.GPIO_ModeDefaultOutputPP=GPIO_MODE_OUTPUT_PP
PI9.GPIO_PuPd=GPIO_NOPULL
PI9.GPIO_Speed=GPIO_SPEED_FREQ_LOW
PI9.Signal=GPIO_Output
ProjectManager.HeapSize=0x200
ProjectManager.StackSize=0x400
ProjectManager.TargetToolchain=STM32CubeIDE
RCC.48MHZClocksFreq_Value=48000000
RCC.AHBFreq_Value=168000000
RCC.APB1CLKDivider=RCC_HCLK_DIV4
RCC.APB1Freq_Value=42000000
RCC.APB1TimFreq_Value=84000000
RCC.APB2CLKDivider=RCC_HCLK_DIV2
RCC.APB2Freq_Value=84000000
RCC.APB2TimFreq_Value=168000000
RCC.CortexFreq_Value=168000000
RCC.HCLKFreq_Value=168000000
RCC.HSE_VALUE=25000000
RCC.HSI_VALUE=16000000
RCC.PLLM=25
RCC.PLLN=336
RCC.PLLQ=7
RCC.RCC_MCO1Source=RCC_MCO1SOURCE_HSE
RCC.SYSCLKFreq_VALUE=168000000
RCC.SYSCLKSource=RCC_SYSCLKSOURCE_PLLCLK
RCC.VCOOutputFreq_Value=336000000
SDIO.BusWide-SD_1_bit=SDIO_BUS_WIDE_1B
SH.COMP_DAC1_group.0=DAC_OUT1,DAC_OUT1
SH.FSMC_A0.0=FSMC_A0,21b-a1
SH.FSMC_A0.1=FSMC_A0,21b-a2
SH.FSMC_A0.2=FSMC_A0,21b-a3
SH.FSMC_A1.0=FSMC_A1,21b-a1
SH.FSMC_A1.1=FSMC_A1,21b-a2
SH.FSMC_A1.2=FSMC_A1,21b-a3
SH.FSMC_A10.0=FSMC_A10,21b-a1
SH.FSMC_A10.1=FSMC_A10,21b-a2
SH.FSMC_A10.2=FSMC_A10,21b-a3
SH.FSMC_A11.0=FSMC_A11,21b-a1
SH.FSMC_A11.1=FSMC_A11,21b-a2
SH.FSMC_A11.2=FSMC_A11,21b-a3
SH.FSMC_A12.0=FSMC_A12,21b-a1
SH.FSMC_A12.1=FSMC_A12,21b-a2
SH.FSMC_A12.2=FSMC_A12,21b-a3
SH.FSMC_A13.0=FSMC_A13,21b-a1
SH.FSMC_A13.1=FSMC_A13,21b-a2
SH.FSMC_A13.2=FSMC_A13,21b-a3
SH.FSMC_A14.0=FSMC_A14,21b-a1
SH.FSMC_A14.1=FSMC_A14,21b-a2
SH.FSMC_A14.2=FSMC_A14,21b-a3
SH.FSMC_A15.0=FSMC_A15,21b-a1
SH.FSMC_A15.1=FSMC_A15,21b-a2
SH.FSMC_A15.2=FSMC_A15,21b-a3
SH.FSMC_A16_CLE.0=FSMC_A16,21b-a1
SH.FSMC_A16_CLE.1=FSMC_A16,21b-a2
SH.FSMC_A16_CLE.2=FSMC_A16,21b-a3
SH.FSMC_A17_ALE.0=FSMC_A17,21b-a1
SH.FSMC_A17_ALE.1=FSMC_A17,21b-a2
SH.FSMC_A17_ALE.2=FSMC_A17,21b-a3
SH.FSMC_A18.0=FSMC_A18,21b-a1
SH.FSMC_A18.1=FSMC_A18,21b-a2
SH.FSMC_A18.2=FSMC_A18,21b-a3
SH.FSMC_A19.0=FSMC_A19,21b-a1
SH.FSMC_A19.1=FSMC_A19,21b-a2
SH.FSMC_A19.2=FSMC_A19,21b-a3
SH.FSMC_A2.0=FSMC_A2,21b-a1
SH.FSMC_A2.1=FSMC_A2,21b-a2
SH.FSMC_A2.2=FSMC_A2,21b-a3
SH.FSMC_A20.0=FSMC_A20,21b-a1
SH.FSMC_A20.1=FSMC_A20,21b-a2
SH.FSMC_A20.2=FSMC_A20,21b-a3
SH.FSMC_A3.0=FSMC_A3,21b-a1
SH.FSMC_A3.1=FSMC_A3,21b-a2
SH.FSMC_A3.2=FSMC_A3,21b-a3
SH.FSMC_A4.0=FSMC_A4,21b-a1
SH.FSMC_A4.1=FSMC_A4,21b-a2
SH.FSMC_A4.2=FSMC_A4,21b-a3
SH.FSMC_A5.0=FSMC_A5,21b-a1
SH.FSMC_A5.1=FSMC_A5,21b-a2
SH.FSMC_A5.2=FSMC_A5,21b-a3
SH.FSMC_A6.0=FSMC_A6,21b-a1
SH.FSMC_A6.1=FSMC_A6,21b-a2
SH.FSMC_A6.2=FSMC_A6,21b-a3
SH.FSMC_A7.0=FSMC_A7,21b-a1
SH.FSMC_A7.1=FSMC_A7,21b-a2
SH.FSMC_A7.2=FSMC_A7,21b-a3
SH.FSMC_A8.0=FSMC_A8,21b-a1
SH.FSMC_A8.1=FSMC_A8,21b-a2
SH.FSMC_A8.2=FSMC_A8,21b-a3
SH.FSMC_A9.0=FSMC_A9,21b-a1
SH.FSMC_A9.1=FSMC_A9,21b-a2
SH.FSMC_A9.2=FSMC_A9,21b-a3
SH.FSMC_CLK.0=FSMC_CLK
SH.FSMC_D0_DA0.0=FSMC_D0,16b-d1
SH.FSMC_D0_DA0.1=FSMC_D0,16b-d2
SH.FSMC_D0_DA0.2=FSMC_D0,16b-d3
SH.FSMC_D10_DA10.0=FSMC_D10,16b-d1
SH.FSMC_D10_DA10.1=FSMC_D10,16b-d2
SH.FSMC_D10_DA10.2=FSMC_D10,16b-d3
SH.FSMC_D11_DA11.0=FSMC_D11,16b-d1
SH.FSMC_D11_DA11.1=FSMC_D11,16b-d2
SH.FSMC_D11_DA11.2=FSMC_D11,16b-d3
SH.FSMC_D12_DA12.0=FSMC_D12,16b-d1
SH.FSMC_D12_DA12.1=FSMC_D12,16b-d2
SH.FSMC_D12_DA12.2=FSMC_D12,16b-d3
SH.FSMC_D13_DA13.0=FSMC_D13,16b-d1
SH.FSMC_D13_DA13.1=FSMC_D13,16b-d2
SH.FSMC_D13_DA13.2=FSMC_D13,16b-d3
SH.FSMC_D14_DA14.0=FSMC_D14,16b-d1
SH.FSMC_D14_DA14.1=FSMC_D14,16b-d2
SH.FSMC_D14_DA14.2=FSMC_D14,16b-d3
SH.FSMC_D15_DA15.0=FSMC_D15,16b-d1
SH.FSMC_D15_DA15.1=FSMC_D15,16b-d2
SH.FSMC_D15_DA15.2=FSMC_D15,16b-d3
SH.FSMC_D1_DA1.0=FSMC_D1,16b-d1
SH.FSMC_D1_DA1.1=FSMC_D1,16b-d2
SH.FSMC_D1_DA1.2=FSMC_D1,16b-d3
SH.FSMC_D2_DA2.0=FSMC_D2,16b-d1
SH.FSMC_D2_DA2.1=FSMC_D2,16b-d2
SH.FSMC_D2_DA2.2=FSMC_D2,16b-d3
SH.FSMC_D3_DA3.0=FSMC_D3,16b-d1
SH.FSMC_D3_DA3.1=FSMC_D3,16b-d2
SH.FSMC_D3_DA3.2=FSMC_D3,16b-d3
SH.FSMC_D4_DA4.0=FSMC_D4,16b-d1
SH.FSMC_D4_DA4.1=FSMC_D4,16b-d2
SH.FSMC_D4_DA4.2=FSMC_D4,16b-d3
SH.FSMC_D5_DA5.0=FSMC_D5,16b-d1
SH.FSMC_D5_DA5.1=FSMC_D5,16b-d2
SH.FSMC_D5_DA5.2=FSMC_D5,16b-d3
SH.FSMC_D6_DA6.0=FSMC_D6,16b-d1
SH.FSMC_D6_DA6.1=FSMC_D6,16b-d2
SH.FSMC_D6_DA6.2=FSMC_D6,16b-d3
SH.FSMC_D7_DA7.0=FSMC_D7,16b-d1
SH.FSMC_D7_DA7.1=FSMC_D7,16b-d2
SH.FSMC_D7_DA7.2=FSMC_D7,16b-d3
SH.FSMC_D8_DA8.0=FSMC_D8,16b-d1
SH.FSMC_D8_DA8.1=FSMC_D8,16b-d2
SH.FSMC_D8_DA8.2=FSMC_D8,16b-d3
SH.FSMC_D9_DA9.0=FSMC_D9,16b-d1
SH.FSMC_D9_DA9.1=FSMC_D9,16b-d2
SH.FSMC_D9_DA9.2=FSMC_D9,16b-d3
SH.FSMC_NBL0.0=FSMC_NBL0,2ByteEnable2
SH.FSMC_NBL1.0=FSMC_NBL1,2ByteEnable2
SH.FSMC_NL.0=FSMC_NL
SH.FSMC_NOE.0=FSMC_NOE,NorFlash1
SH.FSMC_NOE.1=FSMC_NOE,Sram2
SH.FSMC_NOE.2=FSMC_NOE,Sram3
SH.FSMC_NWAIT.0=FSMC_NWAIT
SH.FSMC_NWE.0=FSMC_NWE,NorFlash1
SH.FSMC_NWE.1=FSMC_NWE,Sram2
SH.FSMC_NWE.2=FSMC_NWE,Sram3
SPI2.BaudRatePrescaler=SPI_BAUDRATEPRESCALER_16
SPI2.CalculateBaudRate=2.625 MBits/s
SPI2.Direction=SPI_DIRECTION_1LINE
SPI2.Mode=SPI_MODE_MASTER
SPI2.VirtualType=VM_MASTER
USART3.VirtualMode=VM_ASYNC
USB_HOST.BSP.number=1
USB_HOST.USBH_HandleTypeDef-CDC_FS=hUsbHostFS
USB_HOST.USBH_USE_OS-CDC_FS=0
USB_HOST.VirtualModeFS=Cdc
USB_HOST0.BSP.STBoard=false
USB_HOST0.BSP.api=Unknown
USB_HOST0.BSP.instance=PH5
USB_HOST0.BSP.ip=GPIO
USB_HOST0.BSP.mode=Output
USB_HOST0.BSP.name=Drive_VBUS_FS
USB_HOST0.BSP.solution=PH5
USB_OTG_FS.VirtualMode=Host_Only
USB_OTG_FS.phy_itface=HCD_PHY_EMBEDDED
USB_OTG_HS.VirtualMode-Host_HS=Host_HS
VP_FATFS_VS_SDIO.Mode=SDIO
VP_FREERTOS_VS_CMSIS_V1.Mode=CMSIS_V1
VP_USB_HOST_VS_USB_HOST_CDC_FS.Mode=CDC_FS
board=STM3240G-EVAL

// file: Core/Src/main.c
/* USER CODE BEGIN Header */
/**
  ******************************************************************************
  * @file           : main.c
  * @brief          : Main program body
  ******************************************************************************
  * @attention
  *
  * Copyright (c) 2024 STMicroelectronics.
  * All rights reserved.
  *
  * This software is licensed under terms that can be found in the LICENSE file
  * in the root directory of this software component.
  * If no LICENSE file comes with this software, it is provided AS-IS.
  *
  ******************************************************************************
  */
/* USER CODE END Header */
#include "main.h"
#include "string.h"
#include "cmsis_os.h"
#include "fatfs.h"
#include "usb_host.h"

ETH_TxPacketConfig TxConfig;
ETH_DMADescTypeDef  DMARxDscrTab[ETH_RX_DESC_CNT]; /* Ethernet Rx DMA Descriptors */
ETH_DMADescTypeDef  DMATxDscrTab[ETH_TX_DESC_CNT]; /* Ethernet Tx DMA Descriptors */

ADC_HandleTypeDef hadc3;

DAC_HandleTypeDef hdac;

DCMI_HandleTypeDef hdcmi;

ETH_HandleTypeDef heth;

I2C_HandleTypeDef hi2c1;

SD_HandleTypeDef hsd;

SPI_HandleTypeDef hspi2;
DMA_HandleTypeDef hdma_spi2_tx;

UART_HandleTypeDef huart3;

HCD_HandleTypeDef hhcd_USB_OTG_HS;

NOR_HandleTypeDef hnor1;
SRAM_HandleTypeDef hsram2;
SRAM_HandleTypeDef hsram3;

osThreadId defaultTaskHandle;
/* USER CODE BEGIN PV */
//Frame buffers
/*Static or global buffer(s). The second buffer is optional*/
static lv_color_t buf_1[3200]; //TODO: Chose a buffer size. DISPLAY_WIDTH * 10 is one suggestion.

/* USER CODE END PV */

void SystemClock_Config(void);
static void MX_GPIO_Init(void);
static void MX_DMA_Init(void);
static void MX_ADC3_Init(void);
static void MX_DAC_Init(void);
static void MX_DCMI_Init(void);
static void MX_ETH_Init(void);
static void MX_FSMC_Init(void);
static void MX_I2C1_Init(void);
static void MX_SDIO_SD_Init(void);
static void MX_USART3_UART_Init(void);
static void MX_USB_OTG_HS_HCD_Init(void);
static void MX_SPI2_Init(void);
void StartDefaultTask(void const * argument);

int main(void)
{

  /* MCU Configuration--------------------------------------------------------*/

  /* Reset of all peripherals, Initializes the Flash interface and the Systick. */
  HAL_Init();

  /* Configure the system clock */
  SystemClock_Config();

  /* Initialize all configured peripherals */
  MX_GPIO_Init();
  MX_DMA_Init();
  MX_ADC3_Init();
  MX_DAC_Init();
  MX_DCMI_Init();
  MX_ETH_Init();
  MX_FSMC_Init();
  MX_I2C1_Init();
  MX_SDIO_SD_Init();
  MX_USART3_UART_Init();
  MX_USB_OTG_HS_HCD_Init();
  MX_FATFS_Init();
  MX_SPI2_Init();
  /* USER CODE BEGIN 2 */
  //BSP_LCD_Init();
  lv_init();
  Display_Init();
  BSP_SRAM_Init();
    /* Initialize the touch screen */
    BSP_TS_Init(BSP_LCD_GetXSize(), BSP_LCD_GetYSize());

    /* Initialize LittlevGL */

    //BSP_LCD_Clear(LCD_COLOR_BLACK);
    static lv_style_t style_shadow;
        lv_style_init(&style_shadow);
        lv_style_set_text_opa(&style_shadow, LV_OPA_30);
        lv_style_set_text_color(&style_shadow, lv_color_black());

        /*Create a label for the shadow first (it's in the background)*/
        lv_obj_t * shadow_label = lv_label_create(lv_scr_act());
        lv_obj_add_style(shadow_label, &style_shadow, 0);

        /*Create the main label*/
        lv_obj_t * main_label = lv_label_create(lv_scr_act());
        lv_label_set_text(main_label, "A simple method to create\n"
                          "shadows on a text.\n"
                          "It even works with\n\n"
                          "newlines     and spaces.");

        /*Set the same text for the shadow label*/
        lv_label_set_text(shadow_label, lv_label_get_text(main_label));

        /*Position the main label*/
        lv_obj_align(main_label, LV_ALIGN_CENTER, 0, 0);

        /*Shift the second label down and to the right by 2 pixel*/
        lv_obj_align_to(shadow_label, main_label, LV_ALIGN_TOP_LEFT, 2, 2);
  /* USER CODE END 2 */

  /* Create the thread(s) */
  /* definition and creation of defaultTask */
  osThreadDef(defaultTask, StartDefaultTask, osPriorityNormal, 0, 128);
  defaultTaskHandle = osThreadCreate(osThread(defaultTask), NULL);

  /* Start scheduler */
  osKernelStart();

  /* We should never get here as control is now taken by the scheduler */
  /* Infinite loop */
  while (1)
  {

  }
}

void SystemClock_Config(void)
{
  RCC_OscInitTypeDef RCC_OscInitStruct = {0};
  RCC_ClkInitTypeDef RCC_ClkInitStruct = {0};

  /** Configure the main internal regulator output voltage
  */
  __HAL_RCC_PWR_CLK_ENABLE();
  __HAL_PWR_VOLTAGESCALING_CONFIG(PWR_REGULATOR_VOLTAGE_SCALE1);

  /** Initializes the RCC Oscillators according to the specified parameters
  * in the RCC_OscInitTypeDef structure.
  */
  RCC_OscInitStruct.OscillatorType = RCC_OSCILLATORTYPE_HSE;
  RCC_OscInitStruct.HSEState = RCC_HSE_ON;
  RCC_OscInitStruct.PLL.PLLState = RCC_PLL_ON;
  RCC_OscInitStruct.PLL.PLLSource = RCC_PLLSOURCE_HSE;
  RCC_OscInitStruct.PLL.PLLM = 25;
  RCC_OscInitStruct.PLL.PLLN = 336;
  RCC_OscInitStruct.PLL.PLLP = RCC_PLLP_DIV2;
  RCC_OscInitStruct.PLL.PLLQ = 7;
  if (HAL_RCC_OscConfig(&RCC_OscInitStruct) != HAL_OK)
  {
    Error_Handler();
  }

  /** Initializes the CPU, AHB and APB buses clocks
  */
  RCC_ClkInitStruct.ClockType = RCC_CLOCKTYPE_HCLK|RCC_CLOCKTYPE_SYSCLK
                              |RCC_CLOCKTYPE_PCLK1|RCC_CLOCKTYPE_PCLK2;
  RCC_ClkInitStruct.SYSCLKSource = RCC_SYSCLKSOURCE_PLLCLK;
  RCC_ClkInitStruct.AHBCLKDivider = RCC_SYSCLK_DIV1;
  RCC_ClkInitStruct.APB1CLKDivider = RCC_HCLK_DIV4;
  RCC_ClkInitStruct.APB2CLKDivider = RCC_HCLK_DIV2;

  if (HAL_RCC_ClockConfig(&RCC_ClkInitStruct, FLASH_LATENCY_5) != HAL_OK)
  {
    Error_Handler();
  }
  HAL_RCC_MCOConfig(RCC_MCO1, RCC_MCO1SOURCE_HSE, RCC_MCODIV_1);
}

static void MX_ADC3_Init(void)
{

  ADC_ChannelConfTypeDef sConfig = {0};

  /** Configure the global features of the ADC (Clock, Resolution, Data Alignment and number of conversion)
  */
  hadc3.Instance = ADC3;
  hadc3.Init.ClockPrescaler = ADC_CLOCK_SYNC_PCLK_DIV4;
  hadc3.Init.Resolution = ADC_RESOLUTION_12B;
  hadc3.Init.ScanConvMode = DISABLE;
  hadc3.Init.ContinuousConvMode = DISABLE;
  hadc3.Init.DiscontinuousConvMode = DISABLE;
  hadc3.Init.ExternalTrigConvEdge = ADC_EXTERNALTRIGCONVEDGE_NONE;
  hadc3.Init.ExternalTrigConv = ADC_SOFTWARE_START;
  hadc3.Init.DataAlign = ADC_DATAALIGN_RIGHT;
  hadc3.Init.NbrOfConversion = 1;
  hadc3.Init.DMAContinuousRequests = DISABLE;
  hadc3.Init.EOCSelection = ADC_EOC_SINGLE_CONV;
  if (HAL_ADC_Init(&hadc3) != HAL_OK)
  {
    Error_Handler();
  }

  /** Configure for the selected ADC regular channel its corresponding rank in the sequencer and its sample time.
  */
  sConfig.Channel = ADC_CHANNEL_7;
  sConfig.Rank = 1;
  sConfig.SamplingTime = ADC_SAMPLETIME_3CYCLES;
  if (HAL_ADC_ConfigChannel(&hadc3, &sConfig) != HAL_OK)
  {
    Error_Handler();
  }

}

static void MX_DAC_Init(void)
{

  DAC_ChannelConfTypeDef sConfig = {0};

  /** DAC Initialization
  */
  hdac.Instance = DAC;
  if (HAL_DAC_Init(&hdac) != HAL_OK)
  {
    Error_Handler();
  }

  /** DAC channel OUT1 config
  */
  sConfig.DAC_Trigger = DAC_TRIGGER_NONE;
  sConfig.DAC_OutputBuffer = DAC_OUTPUTBUFFER_ENABLE;
  if (HAL_DAC_ConfigChannel(&hdac, &sConfig, DAC_CHANNEL_1) != HAL_OK)
  {
    Error_Handler();
  }

}

static void MX_DCMI_Init(void)
{

  hdcmi.Instance = DCMI;
  hdcmi.Init.SynchroMode = DCMI_SYNCHRO_HARDWARE;
  hdcmi.Init.PCKPolarity = DCMI_PCKPOLARITY_FALLING;
  hdcmi.Init.VSPolarity = DCMI_VSPOLARITY_LOW;
  hdcmi.Init.HSPolarity = DCMI_HSPOLARITY_LOW;
  hdcmi.Init.CaptureRate = DCMI_CR_ALL_FRAME;
  hdcmi.Init.ExtendedDataMode = DCMI_EXTEND_DATA_8B;
  hdcmi.Init.JPEGMode = DCMI_JPEG_DISABLE;
  if (HAL_DCMI_Init(&hdcmi) != HAL_OK)
  {
    Error_Handler();
  }

}

static void MX_ETH_Init(void)
{

   static uint8_t MACAddr[6];

  heth.Instance = ETH;
  MACAddr[0] = 0x00;
  MACAddr[1] = 0x80;
  MACAddr[2] = 0xE1;
  MACAddr[3] = 0x00;
  MACAddr[4] = 0x00;
  MACAddr[5] = 0x00;
  heth.Init.MACAddr = &MACAddr[0];
  heth.Init.MediaInterface = HAL_ETH_MII_MODE;
  heth.Init.TxDesc = DMATxDscrTab;
  heth.Init.RxDesc = DMARxDscrTab;
  heth.Init.RxBuffLen = 1524;

  if (HAL_ETH_Init(&heth) != HAL_OK)
  {
    Error_Handler();
  }

  memset(&TxConfig, 0 , sizeof(ETH_TxPacketConfig));
  TxConfig.Attributes = ETH_TX_PACKETS_FEATURES_CSUM | ETH_TX_PACKETS_FEATURES_CRCPAD;
  TxConfig.ChecksumCtrl = ETH_CHECKSUM_IPHDR_PAYLOAD_INSERT_PHDR_CALC;
  TxConfig.CRCPadCtrl = ETH_CRC_PAD_INSERT;

}

static void MX_I2C1_Init(void)
{

  hi2c1.Instance = I2C1;
  hi2c1.Init.ClockSpeed = 100000;
  hi2c1.Init.DutyCycle = I2C_DUTYCYCLE_2;
  hi2c1.Init.OwnAddress1 = 0;
  hi2c1.Init.AddressingMode = I2C_ADDRESSINGMODE_7BIT;
  hi2c1.Init.DualAddressMode = I2C_DUALADDRESS_DISABLE;
  hi2c1.Init.OwnAddress2 = 0;
  hi2c1.Init.GeneralCallMode = I2C_GENERALCALL_DISABLE;
  hi2c1.Init.NoStretchMode = I2C_NOSTRETCH_DISABLE;
  if (HAL_I2C_Init(&hi2c1) != HAL_OK)
  {
    Error_Handler();
  }

}

static void MX_SDIO_SD_Init(void)
{

  hsd.Instance = SDIO;
  hsd.Init.ClockEdge = SDIO_CLOCK_EDGE_RISING;
  hsd.Init.ClockBypass = SDIO_CLOCK_BYPASS_DISABLE;
  hsd.Init.ClockPowerSave = SDIO_CLOCK_POWER_SAVE_DISABLE;
  hsd.Init.BusWide = SDIO_BUS_WIDE_1B;
  hsd.Init.HardwareFlowControl = SDIO_HARDWARE_FLOW_CONTROL_DISABLE;
  hsd.Init.ClockDiv = 0;

}

static void MX_SPI2_Init(void)
{

  /* SPI2 parameter configuration*/
  hspi2.Instance = SPI2;
  hspi2.Init.Mode = SPI_MODE_MASTER;
  hspi2.Init.Direction = SPI_DIRECTION_1LINE;
  hspi2.Init.DataSize = SPI_DATASIZE_8BIT;
  hspi2.Init.CLKPolarity = SPI_POLARITY_LOW;
  hspi2.Init.CLKPhase = SPI_PHASE_1EDGE;
  hspi2.Init.NSS = SPI_NSS_SOFT;
  hspi2.Init.BaudRatePrescaler = SPI_BAUDRATEPRESCALER_16;
  hspi2.Init.FirstBit = SPI_FIRSTBIT_MSB;
  hspi2.Init.TIMode = SPI_TIMODE_DISABLE;
  hspi2.Init.CRCCalculation = SPI_CRCCALCULATION_DISABLE;
  hspi2.Init.CRCPolynomial = 10;
  if (HAL_SPI_Init(&hspi2) != HAL_OK)
  {
    Error_Handler();
  }

}

static void MX_USART3_UART_Init(void)
{

  huart3.Instance = USART3;
  huart3.Init.BaudRate = 115200;
  huart3.Init.WordLength = UART_WORDLENGTH_8B;
  huart3.Init.StopBits = UART_STOPBITS_1;
  huart3.Init.Parity = UART_PARITY_NONE;
  huart3.Init.Mode = UART_MODE_TX_RX;
  huart3.Init.HwFlowCtl = UART_HWCONTROL_NONE;
  huart3.Init.OverSampling = UART_OVERSAMPLING_16;
  if (HAL_UART_Init(&huart3) != HAL_OK)
  {
    Error_Handler();
  }

}

static void MX_USB_OTG_HS_HCD_Init(void)
{

  hhcd_USB_OTG_HS.Instance = USB_OTG_HS;
  hhcd_USB_OTG_HS.Init.Host_channels = 12;
  hhcd_USB_OTG_HS.Init.speed = HCD_SPEED_HIGH;
  hhcd_USB_OTG_HS.Init.dma_enable = DISABLE;
  hhcd_USB_OTG_HS.Init.phy_itface = USB_OTG_ULPI_PHY;
  hhcd_USB_OTG_HS.Init.Sof_enable = DISABLE;
  hhcd_USB_OTG_HS.Init.low_power_enable = DISABLE;
  hhcd_USB_OTG_HS.Init.vbus_sensing_enable = DISABLE;
  hhcd_USB_OTG_HS.Init.use_external_vbus = ENABLE;
  if (HAL_HCD_Init(&hhcd_USB_OTG_HS) != HAL_OK)
  {
    Error_Handler();
  }

}

static void MX_DMA_Init(void)
{

  /* DMA controller clock enable */
  __HAL_RCC_DMA1_CLK_ENABLE();

  /* DMA interrupt init */
  /* DMA1_Stream4_IRQn interrupt configuration */
  HAL_NVIC_SetPriority(DMA1_Stream4_IRQn, 5, 0);
  HAL_NVIC_EnableIRQ(DMA1_Stream4_IRQn);

}

static void MX_GPIO_Init(void)
{
  GPIO_InitTypeDef GPIO_InitStruct = {0};

  /* GPIO Ports Clock Enable */
  __HAL_RCC_GPIOE_CLK_ENABLE();
  __HAL_RCC_GPIOB_CLK_ENABLE();
  __HAL_RCC_GPIOG_CLK_ENABLE();
  __HAL_RCC_GPIOD_CLK_ENABLE();
  __HAL_RCC_GPIOC_CLK_ENABLE();
  __HAL_RCC_GPIOA_CLK_ENABLE();
  __HAL_RCC_GPIOI_CLK_ENABLE();
  __HAL_RCC_GPIOH_CLK_ENABLE();
  __HAL_RCC_GPIOF_CLK_ENABLE();

  /*Configure GPIO pin Output Level */
  HAL_GPIO_WritePin(GPIOG, SmartCard_CMDVCC_Pin|LED2_Pin|LED1_Pin, GPIO_PIN_RESET);

  /*Configure GPIO pin Output Level */
  HAL_GPIO_WritePin(LED3_GPIO_Port, LED3_Pin, GPIO_PIN_RESET);

  /*Configure GPIO pin Output Level */
  HAL_GPIO_WritePin(GPIOH, SmartCard_3_5V_Pin|OTG_FS_PowerSwitchOn_Pin, GPIO_PIN_RESET);

  /*Configure GPIO pin Output Level */
  HAL_GPIO_WritePin(LED4_GPIO_Port, LED4_Pin, GPIO_PIN_RESET);

  /*Configure GPIO pin Output Level */
  HAL_GPIO_WritePin(SmartCard_RST_GPIO_Port, SmartCard_RST_Pin, GPIO_PIN_RESET);

  /*Configure GPIO pin : User_Button_Pin */
  GPIO_InitStruct.Pin = User_Button_Pin;
  GPIO_InitStruct.Mode = GPIO_MODE_EVT_RISING;
  GPIO_InitStruct.Pull = GPIO_NOPULL;
  HAL_GPIO_Init(User_Button_GPIO_Port, &GPIO_InitStruct);

  /*Configure GPIO pins : SmartCard_CMDVCC_Pin LED2_Pin LED1_Pin */
  GPIO_InitStruct.Pin = SmartCard_CMDVCC_Pin|LED2_Pin|LED1_Pin;
  GPIO_InitStruct.Mode = GPIO_MODE_OUTPUT_PP;
  GPIO_InitStruct.Pull = GPIO_NOPULL;
  GPIO_InitStruct.Speed = GPIO_SPEED_FREQ_LOW;
  HAL_GPIO_Init(GPIOG, &GPIO_InitStruct);

  /*Configure GPIO pins : I2S_SD_Pin I2S_WS_Pin */
  GPIO_InitStruct.Pin = I2S_SD_Pin|I2S_WS_Pin;
  GPIO_InitStruct.Mode = GPIO_MODE_AF_PP;
  GPIO_InitStruct.Pull = GPIO_NOPULL;
  GPIO_InitStruct.Speed = GPIO_SPEED_FREQ_LOW;
  GPIO_InitStruct.Alternate = GPIO_AF5_SPI2;
  HAL_GPIO_Init(GPIOI, &GPIO_InitStruct);

  /*Configure GPIO pin : IO_Expander_INT_Pin */
  GPIO_InitStruct.Pin = IO_Expander_INT_Pin;
  GPIO_InitStruct.Mode = GPIO_MODE_EVT_RISING;
  GPIO_InitStruct.Pull = GPIO_NOPULL;
  HAL_GPIO_Init(IO_Expander_INT_GPIO_Port, &GPIO_InitStruct);

  /*Configure GPIO pin : LED3_Pin */
  GPIO_InitStruct.Pin = LED3_Pin;
  GPIO_InitStruct.Mode = GPIO_MODE_OUTPUT_PP;
  GPIO_InitStruct.Pull = GPIO_NOPULL;
  GPIO_InitStruct.Speed = GPIO_SPEED_FREQ_LOW;
  HAL_GPIO_Init(LED3_GPIO_Port, &GPIO_InitStruct);

  /*Configure GPIO pins : SmartCard_3_5V_Pin OTG_FS_PowerSwitchOn_Pin */
  GPIO_InitStruct.Pin = SmartCard_3_5V_Pin|OTG_FS_PowerSwitchOn_Pin;
  GPIO_InitStruct.Mode = GPIO_MODE_OUTPUT_PP;
  GPIO_InitStruct.Pull = GPIO_NOPULL;
  GPIO_InitStruct.Speed = GPIO_SPEED_FREQ_LOW;
  HAL_GPIO_Init(GPIOH, &GPIO_InitStruct);

  /*Configure GPIO pin : MicroSDCard_Detect_Pin */
  GPIO_InitStruct.Pin = MicroSDCard_Detect_Pin;
  GPIO_InitStruct.Mode = GPIO_MODE_INPUT;
  GPIO_InitStruct.Pull = GPIO_PULLUP;
  HAL_GPIO_Init(MicroSDCard_Detect_GPIO_Port, &GPIO_InitStruct);

  /*Configure GPIO pin : MCO_Pin */
  GPIO_InitStruct.Pin = MCO_Pin;
  GPIO_InitStruct.Mode = GPIO_MODE_AF_PP;
  GPIO_InitStruct.Pull = GPIO_NOPULL;
  GPIO_InitStruct.Speed = GPIO_SPEED_FREQ_LOW;
  GPIO_InitStruct.Alternate = GPIO_AF0_MCO;
  HAL_GPIO_Init(MCO_GPIO_Port, &GPIO_InitStruct);

  /*Configure GPIO pin : LED4_Pin */
  GPIO_InitStruct.Pin = LED4_Pin;
  GPIO_InitStruct.Mode = GPIO_MODE_OUTPUT_PP;
  GPIO_InitStruct.Pull = GPIO_NOPULL;
  GPIO_InitStruct.Speed = GPIO_SPEED_FREQ_LOW;
  HAL_GPIO_Init(LED4_GPIO_Port, &GPIO_InitStruct);

  /*Configure GPIO pin : SmartCard_CLK_Pin */
  GPIO_InitStruct.Pin = SmartCard_CLK_Pin;
  GPIO_InitStruct.Mode = GPIO_MODE_AF_PP;
  GPIO_InitStruct.Pull = GPIO_NOPULL;
  GPIO_InitStruct.Speed = GPIO_SPEED_FREQ_LOW;
  GPIO_InitStruct.Alternate = GPIO_AF8_USART6;
  HAL_GPIO_Init(SmartCard_CLK_GPIO_Port, &GPIO_InitStruct);

  /*Configure GPIO pin : SmartCard_RST_Pin */
  GPIO_InitStruct.Pin = SmartCard_RST_Pin;
  GPIO_InitStruct.Mode = GPIO_MODE_OUTPUT_PP;
  GPIO_InitStruct.Pull = GPIO_NOPULL;
  GPIO_InitStruct.Speed = GPIO_SPEED_FREQ_LOW;
  HAL_GPIO_Init(SmartCard_RST_GPIO_Port, &GPIO_InitStruct);

  /*Configure GPIO pin : SmartCard_OFF_Pin */
  GPIO_InitStruct.Pin = SmartCard_OFF_Pin;
  GPIO_InitStruct.Mode = GPIO_MODE_INPUT;
  GPIO_InitStruct.Pull = GPIO_NOPULL;
  HAL_GPIO_Init(SmartCard_OFF_GPIO_Port, &GPIO_InitStruct);

  /*Configure GPIO pin : SW1_Pin */
  GPIO_InitStruct.Pin = SW1_Pin;
  GPIO_InitStruct.Mode = GPIO_MODE_INPUT;
  GPIO_InitStruct.Pull = GPIO_NOPULL;
  HAL_GPIO_Init(SW1_GPIO_Port, &GPIO_InitStruct);

  /*Configure GPIO pin : OTG_FS_OverCurrent_Pin */
  GPIO_InitStruct.Pin = OTG_FS_OverCurrent_Pin;
  GPIO_InitStruct.Mode = GPIO_MODE_EVT_RISING;
  GPIO_InitStruct.Pull = GPIO_NOPULL;
  HAL_GPIO_Init(OTG_FS_OverCurrent_GPIO_Port, &GPIO_InitStruct);

  /*Configure GPIO pin : MII_INT_Pin */
  GPIO_InitStruct.Pin = MII_INT_Pin;
  GPIO_InitStruct.Mode = GPIO_MODE_EVT_RISING;
  GPIO_InitStruct.Pull = GPIO_NOPULL;
  HAL_GPIO_Init(MII_INT_GPIO_Port, &GPIO_InitStruct);

}

/* FSMC initialization function */
static void MX_FSMC_Init(void)
{

  FSMC_NORSRAM_TimingTypeDef Timing = {0};

  /** Perform the NOR1 memory initialization sequence
  */
  hnor1.Instance = FSMC_NORSRAM_DEVICE;
  hnor1.Extended = FSMC_NORSRAM_EXTENDED_DEVICE;
  /* hnor1.Init */
  hnor1.Init.NSBank = FSMC_NORSRAM_BANK1;
  hnor1.Init.DataAddressMux = FSMC_DATA_ADDRESS_MUX_DISABLE;
  hnor1.Init.MemoryType = FSMC_MEMORY_TYPE_NOR;
  hnor1.Init.MemoryDataWidth = FSMC_NORSRAM_MEM_BUS_WIDTH_16;
  hnor1.Init.BurstAccessMode = FSMC_BURST_ACCESS_MODE_DISABLE;
  hnor1.Init.WaitSignalPolarity = FSMC_WAIT_SIGNAL_POLARITY_LOW;
  hnor1.Init.WrapMode = FSMC_WRAP_MODE_DISABLE;
  hnor1.Init.WaitSignalActive = FSMC_WAIT_TIMING_BEFORE_WS;
  hnor1.Init.WriteOperation = FSMC_WRITE_OPERATION_DISABLE;
  hnor1.Init.WaitSignal = FSMC_WAIT_SIGNAL_DISABLE;
  hnor1.Init.ExtendedMode = FSMC_EXTENDED_MODE_DISABLE;
  hnor1.Init.AsynchronousWait = FSMC_ASYNCHRONOUS_WAIT_DISABLE;
  hnor1.Init.WriteBurst = FSMC_WRITE_BURST_DISABLE;
  hnor1.Init.PageSize = FSMC_PAGE_SIZE_NONE;
  /* Timing */
  Timing.AddressSetupTime = 15;
  Timing.AddressHoldTime = 15;
  Timing.DataSetupTime = 255;
  Timing.BusTurnAroundDuration = 15;
  Timing.CLKDivision = 16;
  Timing.DataLatency = 17;
  Timing.AccessMode = FSMC_ACCESS_MODE_A;
  /* ExtTiming */

  if (HAL_NOR_Init(&hnor1, &Timing, NULL) != HAL_OK)
  {
    Error_Handler( );
  }

  /** Perform the SRAM2 memory initialization sequence
  */
  hsram2.Instance = FSMC_NORSRAM_DEVICE;
  hsram2.Extended = FSMC_NORSRAM_EXTENDED_DEVICE;
  /* hsram2.Init */
  hsram2.Init.NSBank = FSMC_NORSRAM_BANK2;
  hsram2.Init.DataAddressMux = FSMC_DATA_ADDRESS_MUX_DISABLE;
  hsram2.Init.MemoryType = FSMC_MEMORY_TYPE_SRAM;
  hsram2.Init.MemoryDataWidth = FSMC_NORSRAM_MEM_BUS_WIDTH_16;
  hsram2.Init.BurstAccessMode = FSMC_BURST_ACCESS_MODE_DISABLE;
  hsram2.Init.WaitSignalPolarity = FSMC_WAIT_SIGNAL_POLARITY_LOW;
  hsram2.Init.WrapMode = FSMC_WRAP_MODE_DISABLE;
  hsram2.Init.WaitSignalActive = FSMC_WAIT_TIMING_BEFORE_WS;
  hsram2.Init.WriteOperation = FSMC_WRITE_OPERATION_DISABLE;
  hsram2.Init.WaitSignal = FSMC_WAIT_SIGNAL_DISABLE;
  hsram2.Init.ExtendedMode = FSMC_EXTENDED_MODE_DISABLE;
  hsram2.Init.AsynchronousWait = FSMC_ASYNCHRONOUS_WAIT_DISABLE;
  hsram2.Init.WriteBurst = FSMC_WRITE_BURST_DISABLE;
  hsram2.Init.PageSize = FSMC_PAGE_SIZE_NONE;
  /* Timing */
  Timing.AddressSetupTime = 15;
  Timing.AddressHoldTime = 15;
  Timing.DataSetupTime = 255;
  Timing.BusTurnAroundDuration = 15;
  Timing.CLKDivision = 16;
  Timing.DataLatency = 17;
  Timing.AccessMode = FSMC_ACCESS_MODE_A;
  /* ExtTiming */

  if (HAL_SRAM_Init(&hsram2, &Timing, NULL) != HAL_OK)
  {
    Error_Handler( );
  }

  /** Perform the SRAM3 memory initialization sequence
  */
  hsram3.Instance = FSMC_NORSRAM_DEVICE;
  hsram3.Extended = FSMC_NORSRAM_EXTENDED_DEVICE;
  /* hsram3.Init */
  hsram3.Init.NSBank = FSMC_NORSRAM_BANK3;
  hsram3.Init.DataAddressMux = FSMC_DATA_ADDRESS_MUX_DISABLE;
  hsram3.Init.MemoryType = FSMC_MEMORY_TYPE_SRAM;
  hsram3.Init.MemoryDataWidth = FSMC_NORSRAM_MEM_BUS_WIDTH_16;
  hsram3.Init.BurstAccessMode = FSMC_BURST_ACCESS_MODE_DISABLE;
  hsram3.Init.WaitSignalPolarity = FSMC_WAIT_SIGNAL_POLARITY_LOW;
  hsram3.Init.WrapMode = FSMC_WRAP_MODE_DISABLE;
  hsram3.Init.WaitSignalActive = FSMC_WAIT_TIMING_BEFORE_WS;
  hsram3.Init.WriteOperation = FSMC_WRITE_OPERATION_DISABLE;
  hsram3.Init.WaitSignal = FSMC_WAIT_SIGNAL_DISABLE;
  hsram3.Init.ExtendedMode = FSMC_EXTENDED_MODE_DISABLE;
  hsram3.Init.AsynchronousWait = FSMC_ASYNCHRONOUS_WAIT_DISABLE;
  hsram3.Init.WriteBurst = FSMC_WRITE_BURST_DISABLE;
  hsram3.Init.PageSize = FSMC_PAGE_SIZE_NONE;
  /* Timing */
  Timing.AddressSetupTime = 15;
  Timing.AddressHoldTime = 15;
  Timing.DataSetupTime = 255;
  Timing.BusTurnAroundDuration = 15;
  Timing.CLKDivision = 16;
  Timing.DataLatency = 17;
  Timing.AccessMode = FSMC_ACCESS_MODE_A;
  /* ExtTiming */

  if (HAL_SRAM_Init(&hsram3, &Timing, NULL) != HAL_OK)
  {
    Error_Handler( );
  }

}

void StartDefaultTask(void const * argument)
{
  /* init code for USB_HOST */
  MX_USB_HOST_Init();
  for(;;)
  {
    osDelay(1);
  }
}

void Error_Handler(void)
{
  __disable_irq();
  while (1)
  {
  }
}
